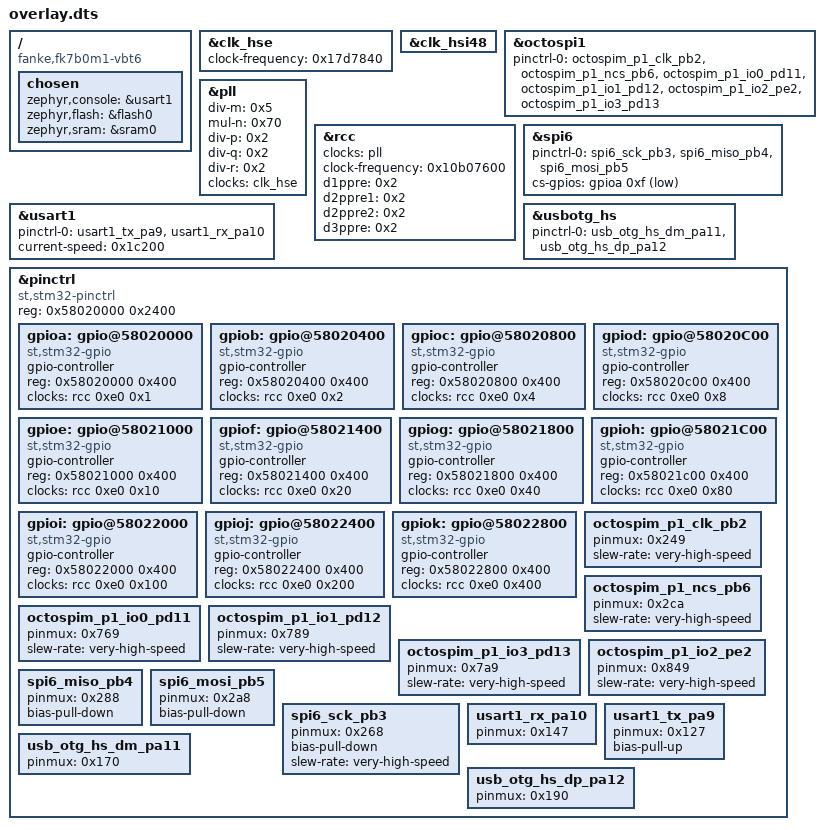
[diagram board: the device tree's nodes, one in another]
/ {
	compatible = "fanke,fk7b0m1-vbt6";
	chosen {
		zephyr,console = &usart1;
		zephyr,flash = &flash0;
		zephyr,sram = &sram0;
	};
};
&clk_hse{
	status = "okay";
	clock-frequency = < 0x17d7840 >;
};
&clk_hsi48{
	status = "okay";
};
&octospi1{
	status = "okay";
	pinctrl-0 = < &octospim_p1_clk_pb2 &octospim_p1_ncs_pb6 &octospim_p1_io0_pd11 &octospim_p1_io1_pd12 &octospim_p1_io2_pe2 &octospim_p1_io3_pd13 >;
	pinctrl-names = "default";
};
&pll{
	status = "okay";
	div-m = < 0x5 >;
	mul-n = < 0x70 >;
	div-p = < 0x2 >;
	div-q = < 0x2 >;
	div-r = < 0x2 >;
	clocks = < &clk_hse >;
};
&rcc{
	clocks = < &pll >;
	clock-frequency = < 0x10b07600 >;
	d1ppre = < 0x2 >;
	d2ppre1 = < 0x2 >;
	d2ppre2 = < 0x2 >;
	d3ppre = < 0x2 >;
};
&spi6{
	status = "okay";
	pinctrl-0 = < &spi6_sck_pb3 &spi6_miso_pb4 &spi6_mosi_pb5 >;
	cs-gpios = < &gpioa 0xf 0x1 >;
	pinctrl-names = "default";
};
&usart1{
	status = "okay";
	pinctrl-0 = < &usart1_tx_pa9 &usart1_rx_pa10 >;
	pinctrl-names = "default";
	current-speed = < 0x1c200 >;
};
&usbotg_hs{
	status = "okay";
	pinctrl-0 = < &usb_otg_hs_dm_pa11 &usb_otg_hs_dp_pa12 >;
	pinctrl-names = "default";
};
&pinctrl{
	compatible = "st,stm32-pinctrl";
	#address-cells = < 0x1 >;
	#size-cells = < 0x1 >;
	reg = < 0x58020000 0x2400 >;
	gpioa: gpio@58020000 {
		compatible = "st,stm32-gpio";
		gpio-controller;
		#gpio-cells = < 0x2 >;
		reg = < 0x58020000 0x400 >;
		clocks = < &rcc 0xe0 0x1 >;
	};
	gpiob: gpio@58020400 {
		compatible = "st,stm32-gpio";
		gpio-controller;
		#gpio-cells = < 0x2 >;
		reg = < 0x58020400 0x400 >;
		clocks = < &rcc 0xe0 0x2 >;
	};
	gpioc: gpio@58020800 {
		compatible = "st,stm32-gpio";
		gpio-controller;
		#gpio-cells = < 0x2 >;
		reg = < 0x58020800 0x400 >;
		clocks = < &rcc 0xe0 0x4 >;
	};
	gpiod: gpio@58020C00 {
		compatible = "st,stm32-gpio";
		gpio-controller;
		#gpio-cells = < 0x2 >;
		reg = < 0x58020c00 0x400 >;
		clocks = < &rcc 0xe0 0x8 >;
	};
	gpioe: gpio@58021000 {
		compatible = "st,stm32-gpio";
		gpio-controller;
		#gpio-cells = < 0x2 >;
		reg = < 0x58021000 0x400 >;
		clocks = < &rcc 0xe0 0x10 >;
	};
	gpiof: gpio@58021400 {
		compatible = "st,stm32-gpio";
		gpio-controller;
		#gpio-cells = < 0x2 >;
		reg = < 0x58021400 0x400 >;
		clocks = < &rcc 0xe0 0x20 >;
	};
	gpiog: gpio@58021800 {
		compatible = "st,stm32-gpio";
		gpio-controller;
		#gpio-cells = < 0x2 >;
		reg = < 0x58021800 0x400 >;
		clocks = < &rcc 0xe0 0x40 >;
	};
	gpioh: gpio@58021C00 {
		compatible = "st,stm32-gpio";
		gpio-controller;
		#gpio-cells = < 0x2 >;
		reg = < 0x58021c00 0x400 >;
		clocks = < &rcc 0xe0 0x80 >;
	};
	gpioi: gpio@58022000 {
		compatible = "st,stm32-gpio";
		gpio-controller;
		#gpio-cells = < 0x2 >;
		reg = < 0x58022000 0x400 >;
		clocks = < &rcc 0xe0 0x100 >;
	};
	gpioj: gpio@58022400 {
		compatible = "st,stm32-gpio";
		gpio-controller;
		#gpio-cells = < 0x2 >;
		reg = < 0x58022400 0x400 >;
		clocks = < &rcc 0xe0 0x200 >;
	};
	gpiok: gpio@58022800 {
		compatible = "st,stm32-gpio";
		gpio-controller;
		#gpio-cells = < 0x2 >;
		reg = < 0x58022800 0x400 >;
		clocks = < &rcc 0xe0 0x400 >;
	};
	octospim_p1_clk_pb2: octospim_p1_clk_pb2 {
		pinmux = < 0x249 >;
		slew-rate = "very-high-speed";
	};
	octospim_p1_ncs_pb6: octospim_p1_ncs_pb6 {
		pinmux = < 0x2ca >;
		slew-rate = "very-high-speed";
	};
	octospim_p1_io0_pd11: octospim_p1_io0_pd11 {
		pinmux = < 0x769 >;
		slew-rate = "very-high-speed";
	};
	octospim_p1_io1_pd12: octospim_p1_io1_pd12 {
		pinmux = < 0x789 >;
		slew-rate = "very-high-speed";
	};
	octospim_p1_io3_pd13: octospim_p1_io3_pd13 {
		pinmux = < 0x7a9 >;
		slew-rate = "very-high-speed";
	};
	octospim_p1_io2_pe2: octospim_p1_io2_pe2 {
		pinmux = < 0x849 >;
		slew-rate = "very-high-speed";
	};
	spi6_miso_pb4: spi6_miso_pb4 {
		pinmux = < 0x288 >;
		bias-pull-down;
	};
	spi6_mosi_pb5: spi6_mosi_pb5 {
		pinmux = < 0x2a8 >;
		bias-pull-down;
	};
	spi6_sck_pb3: spi6_sck_pb3 {
		pinmux = < 0x268 >;
		bias-pull-down;
		slew-rate = "very-high-speed";
	};
	usart1_rx_pa10: usart1_rx_pa10 {
		pinmux = < 0x147 >;
	};
	usart1_tx_pa9: usart1_tx_pa9 {
		pinmux = < 0x127 >;
		bias-pull-up;
	};
	usb_otg_hs_dm_pa11: usb_otg_hs_dm_pa11 {
		pinmux = < 0x170 >;
	};
	usb_otg_hs_dp_pa12: usb_otg_hs_dp_pa12 {
		pinmux = < 0x190 >;
	};
};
